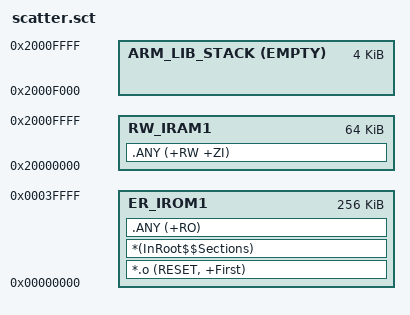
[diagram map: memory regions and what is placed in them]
LR_IROM1 0x00000000 0x00040000 {
  ER_IROM1 0x00000000 0x00040000 {
    *.o (RESET, +First)
    *(InRoot$$Sections)
    .ANY (+RO)
  }
  RW_IRAM1 0x20000000 0x00010000 {
    .ANY (+RW +ZI)
  }
  ARM_LIB_STACK 0x20010000 EMPTY -0x1000 {}
}
